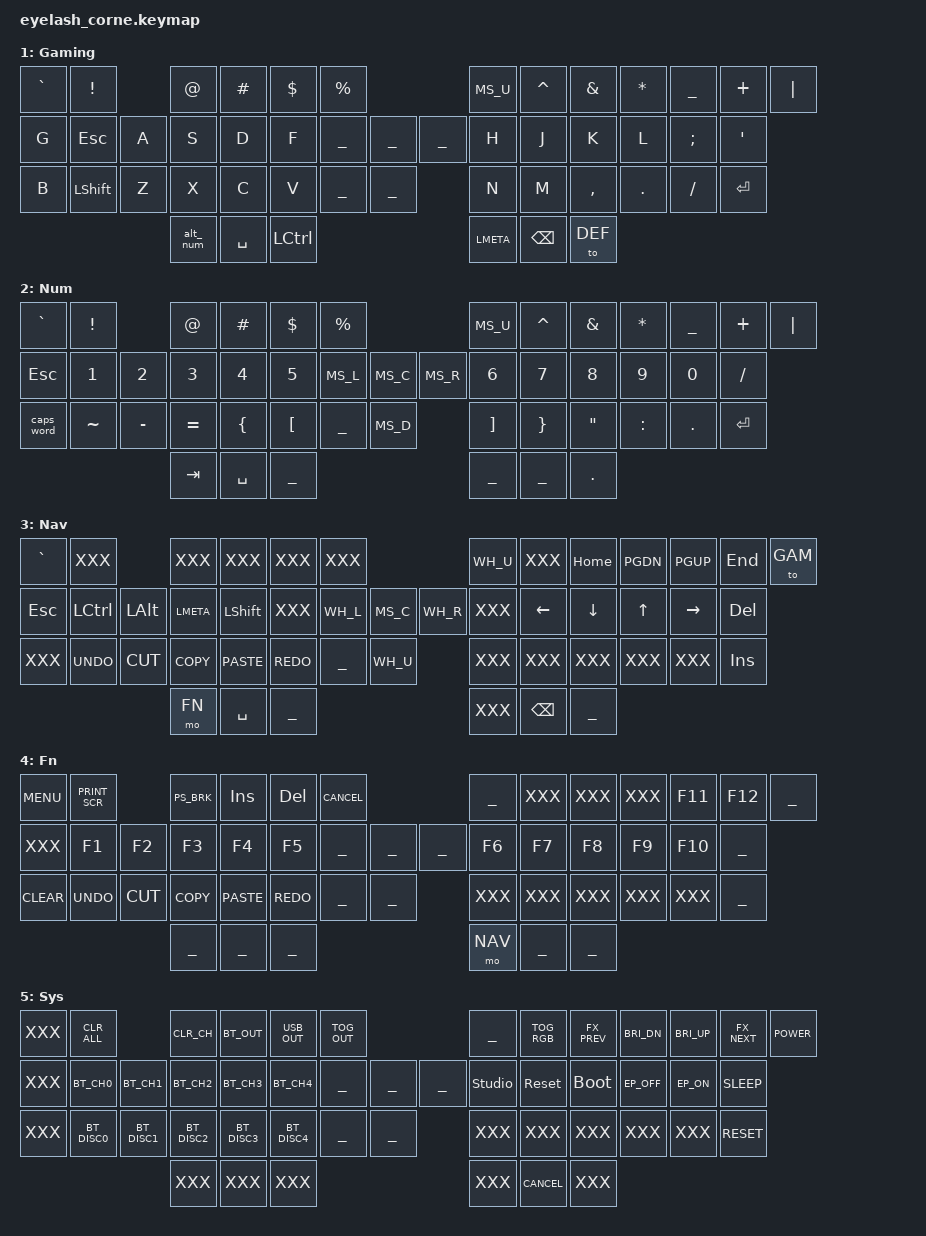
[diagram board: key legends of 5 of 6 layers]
#define CONFIG_WIRELESS

#include "eyelash_matrix.h"
#include "base.keymap"
#include <dt-bindings/zmk/keys.h>

/*
  layout:  the block in the middle is
    - the encoder push button (lower left)
    - the mini joystick & in the center, it's push button

  bindings = <
    XXX XXX XXX XXX XXX XXX     ___      XXX XXX XXX XXX XXX XXX
    XXX XXX XXX XXX XXX XXX ___ ___ ___  XXX XXX XXX XXX XXX XXX
    XXX XXX XXX XXX XXX XXX ___ ___      XXX XXX XXX XXX XXX XXX
                XXX XXX XXX              XXX XXX XXX
  >;
*/

/ {

  /* encoder behaviours */

  rgb_encoder: rgb_encoder {
    compatible = "zmk,behavior-sensor-rotate";
    #sensor-binding-cells = <0>;
    bindings = <&rgb_ug RGB_BRI>, <&rgb_ug RGB_BRD>;
  };

  /* layout */

  keymap {
    compatible = "zmk,keymap";

    /*************************
     * DEF: Gallium default keymap
     *************************/

    default_layer {
      display-name = "Base";

      bindings = <
      ___ &kp LS(F10) Q  &kp W  &as END E  &as LC(LS(Z)) R      &kp T        _UP       &kp Y              &as RC(Z) U       &kp I              &kp O                    &kp P     &as RC(RS(ESC)) MINUS
      mod_to0_mouse_jiggle 0 ESCAPE _HOME_ROW_MODS_LEFT_        &hml LGUI G   _L_ _RT _R_  &as HOME H   _HOME_ROW_MODS_RIGHT_                SLS_MEH
      CMP_SFT &kp Z          &as DEL X        &kp C              &as LC(LA(LS(V))) V  &ltq 6 C_MUTE  _DN    &as N0 B   &as END N          &as PG_DN M       &as PG_UP COMMA    &tap_dot_shift_capsword  &kp FSLH  &as RC(RA(DEL)) EQUAL
                                  &smart_num 7 7     &ltq 4 SPACE         &tap_key_repeat_ltq 10 5          &smart_sk_ltq 6 6  &ltq 7 BACKSPACE  &ltq_nav_word 5 5
       >;

      sensor-bindings = <&inc_dec_kp _UP _DN>;
    };

    /*************************
     * GAM: gaming layer
     *************************/

    gaming_layer {
      display-name = "Gaming";

      // QUERTY, but adjusted for columnar stagger so WASD is in the ESDF position

      bindings = <
      &kp GRAVE  &kp EXCL  &kp AT    &kp HASH  &kp DOLLAR &kp PERCENT          MS_U      &kp CARET &kp AMPS &kp STAR &kp UNDER &kp PLUS &kp PIPE
      &kp G  &kp ESC   &kp A  &kp S     &kp D    &kp F     ___ ___ ___     &kp H      &kp J     &kp K      &kp L    &kp SEMI  &kp SQT
      &kp B  &kp LSHFT &kp Z  &kp X     &kp C    &kp V     ___ ___         &kp N      &kp M     &kp COMMA  &kp DOT  &kp SLASH &kp RET
                              &alt__num &kp SPC  &kp LCTRL                 &kp LMETA  &kp BSPC  &to DEF
      >;

      sensor-bindings = <&inc_dec_kp C_VOLUME_UP C_VOLUME_DOWN>;
    };

    /*************************
     * NUM: numbers & symbols
     *************************/

    num_layer {
      display-name = "Num";

      bindings = <
      &kp GRAVE  &kp EXCL  &kp AT    &kp HASH  &kp DOLLAR &kp PERCENT          MS_U      &kp CARET &kp AMPS &kp STAR &kp UNDER &kp PLUS &kp PIPE
      &kp ESC    &kp N1    &kp N2    &kp N3    &kp N4     &kp N5        MS_L MS_C MS_R   &kp N6    &kp N7   &kp N8   &kp N9    &kp N0   &kp SLASH
      &caps_word &kp TILDE &kp MINUS &kp EQUAL &kp LBRC   &kp LBKT      ___    MS_D      &kp RBKT  &kp RBRC &kp DQT  &kp COLON &kp DOT  &kp ENTER
                                     &kp TAB   &kp SPC    ___                            ___       ___      &kp DOT
      >;

      sensor-bindings = <&inc_dec_kp PG_DN PG_UP>;
    };

    /*************************
     * NAV: Navigation
     *************************/

    nav_layer {
      display-name = "Nav";

      bindings = <
      &kp GRAVE XXX        XXX       XXX        XXX         XXX          WH_U        XXX   &kp HOME &kp PGDN &kp PGUP &kp END   &to GAM
      &kp ESC   &kp LCTRL  &kp LALT  &kp LMETA  &kp LSHFT   XXX     WH_L MS_C WH_R   XXX   &kp LEFT &kp DOWN &kp UP   &kp RIGHT &kp DEL
      XXX       _UNDO      _CUT      _COPY      _PASTE      _REDO   ___  WH_U        XXX   XXX      XXX      XXX      XXX       &kp INS // maybe these work?
                                     &mo FN     &kp SPACE   ___                      XXX   &kp BSPC ___
      >;

      sensor-bindings = <&inc_dec_kp PG_DN PG_UP>;
    };

    /*************************
     * FUN: Function keys & extended keys
     *************************/

    function_layer {
      display-name = "Fn";

      bindings = <
      &kp K_MENU  PRINT_SCR  PS_BRK  &kp INS  &kp DEL  &kp K_CANCEL     ___       XXX       XXX     XXX     &kp F11  &kp F12  ___
      XXX         &kp F1     &kp F2  &kp F3   &kp F4   &kp F5       ___ ___ ___   &kp F6    &kp F7  &kp F8  &kp F9   &kp F10  ___
      &kp CLEAR   _UNDO      _CUT    _COPY    _PASTE   _REDO        ___ ___       XXX       XXX     XXX     XXX      XXX      ___
                                     ___      ___      ___                        &mo NAV   ___     ___
      >;

      sensor-bindings = <&rgb_encoder>;
    };

    /*************************
     * SYS: System - bluetooth, power, etc
     *************************/

    sys_layer {
      display-name = "Sys";

      bindings = <
      XXX  CLR_ALL     CLR_CH   BT_OUT    USB_OUT    TOG_OUT        ___       TOG_RGB         FX_PREV       BRI_DN       BRI_UP   FX_NEXT &kp C_POWER
      XXX  BT_CH0      BT_CH1   BT_CH2    BT_CH3     BT_CH4     ___ ___ ___   &studio_unlock  &sys_reset    &bootloader  _EP_OFF  _EP_ON  &kp K_SLEEP
      XXX  BT_DISC0    BT_DISC1 BT_DISC2  BT_DISC3   BT_DISC4   ___ ___       XXX             XXX           XXX          XXX      XXX     &kp C_RESET
                                XXX       XXX        XXX                      XXX             &kp K_CANCEL  XXX
      >;

      /* XXX  BT_CLR_ALL  BT_CLR   BT_OUT    USB_OUT    TOG_OUT        ___       TOG_RGB         FX_PREV       BRI_DN       BRI_UP   FX_NEXT &kp C_POWER */
      /* XXX  BT_CH0      BT_CH1   BT_CH2    BT_CH3     BT_CH4     ___ ___ ___   &studio_unlock  &sys_reset    &bootloader  _EP_OFF  _EP_ON  &kp K_SLEEP */
      /* XXX  BT_DISC0    BT_DISC1 BT_DISC2  BT_DISC3   BT_DISC4   ___ ___       XXX             XXX           XXX          XXX      XXX     &kp C_RESET */

      sensor-bindings = <&rgb_encoder>;
    };
    // activate SYS when FN + NAV held
    //
    conditional_layers {
      compatible = "zmk,conditional-layers";
      tri_layer {
        if-layers = <NAV FN>;
        then-layer = <SYS>;
      };
    };

  };
};
